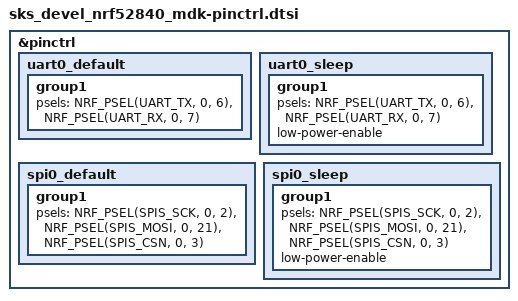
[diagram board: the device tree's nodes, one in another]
/*
 * Copyright (c) 2022 Nordic Semiconductor
 * SPDX-License-Identifier: Apache-2.0
 */

&pinctrl {
	uart0_default: uart0_default {
		group1 {
			psels = <NRF_PSEL(UART_TX, 0, 6)>,
				<NRF_PSEL(UART_RX, 0, 7)>;
		};
	};

	uart0_sleep: uart0_sleep {
		group1 {
			psels = <NRF_PSEL(UART_TX, 0, 6)>,
				<NRF_PSEL(UART_RX, 0, 7)>;
			low-power-enable;
		};
	};

	spi0_default: spi0_default {
		group1 {
			psels = <NRF_PSEL(SPIS_SCK, 0, 2)>,
				// <NRF_PSEL(SPIS_MISO, 0, 20)>,
				<NRF_PSEL(SPIS_MOSI, 0, 21)>,
				<NRF_PSEL(SPIS_CSN, 0, 3)>;
		};
	};	

	spi0_sleep: spi0_sleep {
		group1 {
			psels = <NRF_PSEL(SPIS_SCK, 0, 2)>,
				// <NRF_PSEL(SPIS_MISO, 0, 20)>,
				<NRF_PSEL(SPIS_MOSI, 0, 21)>,
				<NRF_PSEL(SPIS_CSN, 0, 3)>;
			low-power-enable;
		};
	};
};
